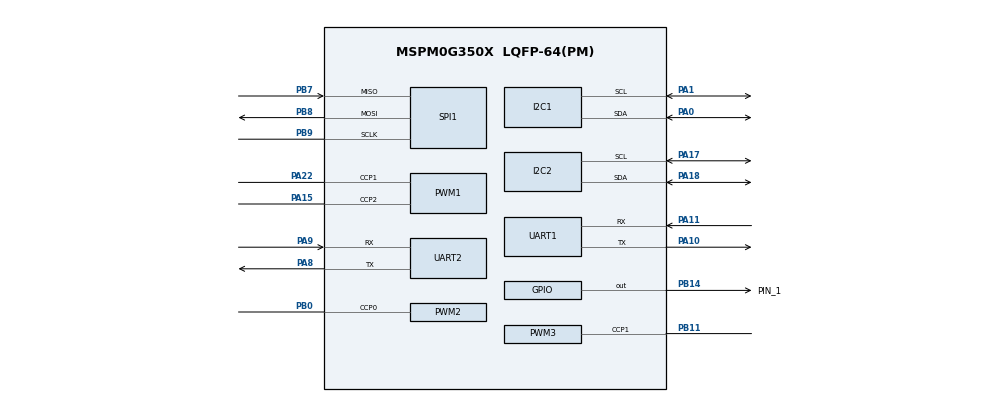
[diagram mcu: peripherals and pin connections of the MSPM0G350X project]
/**
 * @cliArgs --device "MSPM0G350X" --package "LQFP-64(PM)" --part "Default"
 * @versions {"tool":"1.19.0+3426"}
 */

/**
 * Import the modules used in this configuration.
 */
const GPIO   = scripting.addModule("/ti/driverlib/GPIO", {}, false);
const GPIO2  = GPIO.addInstance();
const GPIO6  = GPIO.addInstance();
const GPIO7  = GPIO.addInstance();
const GPIO8  = GPIO.addInstance();
const GPIO9  = GPIO.addInstance();
const GPIO10 = GPIO.addInstance();
const GPIO11 = GPIO.addInstance();
const I2C    = scripting.addModule("/ti/driverlib/I2C", {}, false);
const I2C1   = I2C.addInstance();
const I2C2   = I2C.addInstance();
const PWM    = scripting.addModule("/ti/driverlib/PWM", {}, false);
const PWM1   = PWM.addInstance();
const PWM2   = PWM.addInstance();
const PWM3   = PWM.addInstance();
const SPI    = scripting.addModule("/ti/driverlib/SPI", {}, false);
const SPI1   = SPI.addInstance();
const SYSCTL = scripting.addModule("/ti/driverlib/SYSCTL");
const UART   = scripting.addModule("/ti/driverlib/UART", {}, false);
const UART1  = UART.addInstance();
const UART2  = UART.addInstance();

/**
 * Write custom configuration values to the imported modules.
 */
const Board = scripting.addModule("/ti/driverlib/Board", {}, false);

GPIO2.$name                         = "GPIO_GRP_1";
GPIO2.associatedPins[0].$name       = "PIN_1";
GPIO2.associatedPins[0].pin.$assign = "PB14";

GPIO6.$name                              = "Key_Group";
GPIO6.port                               = "PORTB";
GPIO6.associatedPins.create(3);
GPIO6.associatedPins[0].$name            = "KEY1";
GPIO6.associatedPins[0].assignedPin      = "15";
GPIO6.associatedPins[0].direction        = "INPUT";
GPIO6.associatedPins[0].internalResistor = "PULL_UP";
GPIO6.associatedPins[1].$name            = "KEY2";
GPIO6.associatedPins[1].assignedPin      = "16";
GPIO6.associatedPins[1].direction        = "INPUT";
GPIO6.associatedPins[1].internalResistor = "PULL_UP";
GPIO6.associatedPins[2].$name            = "KEY3";
GPIO6.associatedPins[2].assignedPin      = "2";
GPIO6.associatedPins[2].direction        = "INPUT";
GPIO6.associatedPins[2].internalResistor = "PULL_UP";

GPIO7.$name                              = "Key_PA30";
GPIO7.port                               = "PORTA";
GPIO7.associatedPins[0].$name            = "KEY4";
GPIO7.associatedPins[0].assignedPin      = "30";
GPIO7.associatedPins[0].direction        = "INPUT";
GPIO7.associatedPins[0].internalResistor = "PULL_UP";

GPIO8.$name                         = "Board_Output";
GPIO8.port                          = "PORTB";
GPIO8.associatedPins.create(2);
GPIO8.associatedPins[0].$name       = "STATUS_LED";
GPIO8.associatedPins[0].assignedPin = "4";
GPIO8.associatedPins[1].$name       = "BUZZER";
GPIO8.associatedPins[1].assignedPin = "5";
GPIO8.associatedPins[1].initialValue = "SET";

GPIO9.$name                              = "Right_Encoder";
GPIO9.port                               = "PORTB";
GPIO9.associatedPins.create(2);
GPIO9.associatedPins[0].$name            = "PHA";
GPIO9.associatedPins[0].assignedPin      = "12";
GPIO9.associatedPins[0].direction        = "INPUT";
GPIO9.associatedPins[0].internalResistor = "PULL_UP";
GPIO9.associatedPins[0].interruptEn      = true;
GPIO9.associatedPins[0].polarity         = "RISE_FALL";
GPIO9.associatedPins[1].$name            = "PHB";
GPIO9.associatedPins[1].assignedPin      = "13";
GPIO9.associatedPins[1].direction        = "INPUT";
GPIO9.associatedPins[1].internalResistor = "PULL_UP";
GPIO9.associatedPins[1].interruptEn      = true;
GPIO9.associatedPins[1].polarity         = "RISE_FALL";

GPIO10.$name                         = "IMU_CS";
GPIO10.port                          = "PORTB";
GPIO10.associatedPins[0].$name       = "CS";
GPIO10.associatedPins[0].assignedPin = "6";
GPIO10.associatedPins[0].direction   = "OUTPUT";
GPIO10.associatedPins[0].initialValue = "SET";

GPIO11.$name                              = "Left_Encoder";
GPIO11.port                               = "PORTB";
GPIO11.associatedPins.create(2);
GPIO11.associatedPins[0].$name            = "LEFT_PHA";
GPIO11.associatedPins[0].assignedPin      = "21";
GPIO11.associatedPins[0].direction        = "INPUT";
GPIO11.associatedPins[0].internalResistor = "PULL_UP";
GPIO11.associatedPins[0].interruptEn      = true;
GPIO11.associatedPins[0].polarity         = "RISE_FALL";
GPIO11.associatedPins[1].$name            = "LEFT_PHB";
GPIO11.associatedPins[1].assignedPin      = "22";
GPIO11.associatedPins[1].direction        = "INPUT";
GPIO11.associatedPins[1].internalResistor = "PULL_UP";
GPIO11.associatedPins[1].interruptEn      = true;
GPIO11.associatedPins[1].polarity         = "RISE_FALL";

I2C1.$name                             = "PATH_FISH_I2C";
I2C1.basicEnableController             = true;
I2C1.basicControllerBusSpeed           = 100000;
I2C1.advAnalogGlitchFilter             = "DISABLED";
I2C1.peripheral.$assign                = "I2C0";
I2C1.peripheral.sdaPin.$assign         = "PA0";
I2C1.peripheral.sclPin.$assign         = "PA1";
I2C1.sdaPinConfig.$name                = "Path_Fish_SDA";
I2C1.sclPinConfig.$name                = "Path_Fish_SCL";
I2C1.sdaPinConfig.internalResistor     = "PULL_UP";
I2C1.sclPinConfig.internalResistor     = "PULL_UP";

I2C2.$name                             = "OLED_I2C";
I2C2.basicEnableController             = true;
I2C2.basicControllerBusSpeed           = 400000;
I2C2.advAnalogGlitchFilter             = "DISABLED";
I2C2.peripheral.$assign                = "I2C1";
I2C2.peripheral.sdaPin.$assign         = "PA18";
I2C2.peripheral.sclPin.$assign         = "PA17";
I2C2.sdaPinConfig.$name                = "Oled_SDA";
I2C2.sclPinConfig.$name                = "Oled_SCL";

PWM1.$name                              = "Motor_Left_Timer";
PWM1.timerStartTimer                    = true;
PWM1.clockDivider                       = 8;
PWM1.timerCount                         = 100;
PWM1.ccIndex                            = [1,2];
PWM1.peripheral.$assign                 = "TIMA0";
PWM1.peripheral.ccp1Pin.$assign         = "PA22";
PWM1.peripheral.ccp2Pin.$assign         = "PA15";
PWM1.PWM_CHANNEL_1.$name                = "Motor_Left_AIN1_PWM";
PWM1.PWM_CHANNEL_1.dutyCycle            = 0;
PWM1.PWM_CHANNEL_2.$name                = "Motor_Left_AIN2_PWM";
PWM1.PWM_CHANNEL_2.dutyCycle            = 0;
PWM1.ccp1PinConfig.$name                = "Motor_Left_AIN1_Pin";
PWM1.ccp2PinConfig.$name                = "Motor_Left_AIN2_Pin";

PWM2.$name                              = "Motor_Right_BIN1_Timer";
PWM2.timerStartTimer                    = true;
PWM2.clockDivider                       = 8;
PWM2.timerCount                         = 100;
PWM2.ccIndex                            = [0];
PWM2.peripheral.$assign                 = "TIMA1";
PWM2.peripheral.ccp0Pin.$assign         = "PB0";
PWM2.PWM_CHANNEL_0.$name                = "Motor_Right_BIN1_PWM";
PWM2.PWM_CHANNEL_0.dutyCycle            = 0;
PWM2.ccp0PinConfig.$name                = "Motor_Right_BIN1_Pin";

PWM3.$name                              = "Motor_Right_BIN2_Timer";
PWM3.timerStartTimer                    = true;
PWM3.clockDivider                       = 8;
PWM3.timerCount                         = 100;
PWM3.ccIndex                            = [1];
PWM3.peripheral.$assign                 = "TIMG6";
PWM3.peripheral.ccp1Pin.$assign         = "PB11";
PWM3.PWM_CHANNEL_1.$name                = "Motor_Right_BIN2_PWM";
PWM3.PWM_CHANNEL_1.dutyCycle            = 0;
PWM3.ccp1PinConfig.$name                = "Motor_Right_BIN2_Pin";

SPI1.$name                      = "IMU_SPI";
SPI1.targetBitRate              = 8000000;
SPI1.polarity                   = "0";
SPI1.phase                      = "0";
SPI1.dataSize                   = 8;
SPI1.chipSelect                 = [];
SPI1.frameFormat                = "MOTO3";
SPI1.peripheral.$assign         = "SPI1";
SPI1.peripheral.sclkPin.$assign = "PB9";
SPI1.peripheral.mosiPin.$assign = "PB8";
SPI1.peripheral.misoPin.$assign = "PB7";
SPI1.sclkPinConfig.$name         = "ti_driverlib_gpio_GPIOPinGeneric13";
SPI1.mosiPinConfig.$name         = "ti_driverlib_gpio_GPIOPinGeneric14";
SPI1.misoPinConfig.$name         = "ti_driverlib_gpio_GPIOPinGeneric15";

SYSCTL.forceDefaultClkConfig = true;
SYSCTL.clockTreeEn           = true;

UART1.$name                             = "UART_Debug";
UART1.targetBaudRate                    = 115200;
UART1.enableFIFO                        = true;
UART1.rxFifoThreshold                   = "DL_UART_RX_FIFO_LEVEL_1_4_FULL";
UART1.rxTimeoutValue                    = 15;
UART1.enabledDMARXTriggers              = "DL_UART_DMA_INTERRUPT_RX";
UART1.enabledDMATXTriggers              = "DL_UART_DMA_INTERRUPT_TX";
UART1.enabledInterrupts                 = ["RX_TIMEOUT_ERROR"];
UART1.peripheral.$assign                = "UART0";
UART1.peripheral.rxPin.$assign          = "PA11";
UART1.peripheral.txPin.$assign          = "PA10";
UART1.txPinConfig.direction             = scripting.forceWrite("OUTPUT");
UART1.txPinConfig.hideOutputInversion   = scripting.forceWrite(false);
UART1.txPinConfig.onlyInternalResistor  = scripting.forceWrite(false);
UART1.txPinConfig.passedPeripheralType  = scripting.forceWrite("Digital");
UART1.txPinConfig.$name                 = "ti_driverlib_gpio_GPIOPinGeneric6";
UART1.rxPinConfig.hideOutputInversion   = scripting.forceWrite(false);
UART1.rxPinConfig.onlyInternalResistor  = scripting.forceWrite(false);
UART1.rxPinConfig.passedPeripheralType  = scripting.forceWrite("Digital");
UART1.rxPinConfig.$name                 = "ti_driverlib_gpio_GPIOPinGeneric7";
UART1.DMA_CHANNEL_RX.$name              = "DMA_CH0";
UART1.DMA_CHANNEL_RX.addressMode        = "f2b";
UART1.DMA_CHANNEL_RX.srcLength          = "BYTE";
UART1.DMA_CHANNEL_RX.dstLength          = "BYTE";
UART1.DMA_CHANNEL_RX.peripheral.$assign = "DMA_CH0";
UART1.DMA_CHANNEL_TX.$name              = "DMA_CH1";
UART1.DMA_CHANNEL_TX.addressMode        = "b2f";
UART1.DMA_CHANNEL_TX.srcLength          = "BYTE";
UART1.DMA_CHANNEL_TX.dstLength          = "BYTE";
UART1.DMA_CHANNEL_TX.enableInterrupt    = true;
UART1.DMA_CHANNEL_TX.peripheral.$assign = "DMA_CH1";

UART2.$name                             = "UART_ESP01S";
UART2.targetBaudRate                    = 115200;
UART2.enableFIFO                        = true;
UART2.rxFifoThreshold                   = "DL_UART_RX_FIFO_LEVEL_1_4_FULL";
UART2.rxTimeoutValue                    = 15;
UART2.enabledDMARXTriggers              = "DL_UART_DMA_INTERRUPT_RX";
UART2.enabledDMATXTriggers              = "DL_UART_DMA_INTERRUPT_TX";
UART2.enabledInterrupts                 = ["RX_TIMEOUT_ERROR"];
UART2.peripheral.$assign                = "UART1";
UART2.peripheral.rxPin.$assign          = "PA9";
UART2.peripheral.txPin.$assign          = "PA8";
UART2.txPinConfig.$name                 = "ti_driverlib_gpio_GPIOPinGeneric11";
UART2.txPinConfig.direction             = scripting.forceWrite("OUTPUT");
UART2.txPinConfig.hideOutputInversion   = scripting.forceWrite(false);
UART2.txPinConfig.onlyInternalResistor  = scripting.forceWrite(false);
UART2.txPinConfig.passedPeripheralType  = scripting.forceWrite("Digital");
UART2.rxPinConfig.$name                 = "ti_driverlib_gpio_GPIOPinGeneric12";
UART2.rxPinConfig.hideOutputInversion   = scripting.forceWrite(false);
UART2.rxPinConfig.onlyInternalResistor  = scripting.forceWrite(false);
UART2.rxPinConfig.passedPeripheralType  = scripting.forceWrite("Digital");
UART2.rxPinConfig.enableConfig          = true;
UART2.rxPinConfig.internalResistor      = "PULL_UP";
UART2.DMA_CHANNEL_RX.$name              = "DMA_CH2";
UART2.DMA_CHANNEL_RX.addressMode        = "f2b";
UART2.DMA_CHANNEL_RX.srcLength          = "BYTE";
UART2.DMA_CHANNEL_RX.dstLength          = "BYTE";
UART2.DMA_CHANNEL_RX.peripheral.$assign = "DMA_CH2";
UART2.DMA_CHANNEL_TX.$name              = "DMA_CH3";
UART2.DMA_CHANNEL_TX.addressMode        = "b2f";
UART2.DMA_CHANNEL_TX.srcLength          = "BYTE";
UART2.DMA_CHANNEL_TX.dstLength          = "BYTE";
UART2.DMA_CHANNEL_TX.enableInterrupt    = true;
UART2.DMA_CHANNEL_TX.peripheral.$assign = "DMA_CH3";

/**
 * Pinmux solution for unlocked pins/peripherals. This ensures that minor changes to the automatic solver in a future
 * version of the tool will not impact the pinmux you originally saw.  These lines can be completely deleted in order to
 * re-solve from scratch.
 */
Board.peripheral.$suggestSolution            = "DEBUGSS";
Board.peripheral.swclkPin.$suggestSolution   = "PA20";
Board.peripheral.swdioPin.$suggestSolution   = "PA19";
GPIO6.associatedPins[0].pin.$suggestSolution = "PB15";
GPIO6.associatedPins[1].pin.$suggestSolution = "PB16";
GPIO6.associatedPins[2].pin.$suggestSolution = "PB2";
GPIO7.associatedPins[0].pin.$suggestSolution = "PA30";
GPIO8.associatedPins[0].pin.$suggestSolution = "PB4";
GPIO8.associatedPins[1].pin.$suggestSolution = "PB5";
GPIO9.associatedPins[0].pin.$suggestSolution = "PB12";
GPIO9.associatedPins[1].pin.$suggestSolution = "PB13";
GPIO10.associatedPins[0].pin.$suggestSolution = "PB6";
GPIO11.associatedPins[0].pin.$suggestSolution = "PB21";
GPIO11.associatedPins[1].pin.$suggestSolution = "PB22";
I2C1.peripheral.$suggestSolution              = "I2C0";
I2C2.peripheral.$suggestSolution              = "I2C1";
